# N32MC47x_DP47x register map
Vendor: Nsingtech Ltd.; File version: 1.0
Registers are 32-bit, read-write, reset 0x0 unless marked. A register's access mark holds for its fields unless they carry their own. Offsets are from the block's base; [hi:lo] are bit positions; 'fields as' and 'values as' point back to an identical list.

## FEMC — Flexible external memory controller
Base 0xA0002000
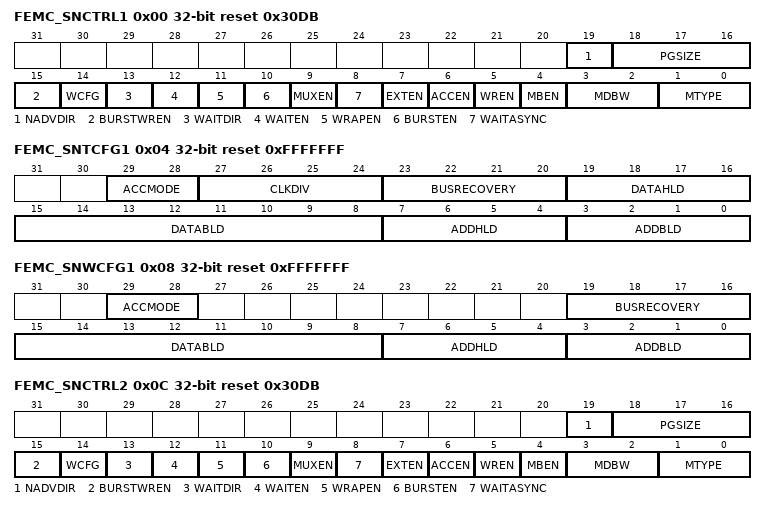
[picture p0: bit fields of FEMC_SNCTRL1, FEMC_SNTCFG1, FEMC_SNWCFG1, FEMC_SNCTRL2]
0x00 FEMC_SNCTRL1 reset 0x30DB
  [19] NADVDIR, [18:16] PGSIZE, [15] BURSTWREN, [14] WCFG, [13] WAITDIR, [12] WAITEN, [11] WRAPEN, [10] BURSTEN, [9] MUXEN, [8] WAITASYNC, [7] EXTEN, [6] ACCEN, [5] WREN, [4] MBEN, [3:2] MDBW, [1:0] MTYPE
0x04 FEMC_SNTCFG1 reset 0xFFFFFFF
  [29:28] ACCMODE, [27:24] CLKDIV, [23:20] BUSRECOVERY, [19:16] DATAHLD, [15:8] DATABLD, [7:4] ADDHLD, [3:0] ADDBLD
0x08 FEMC_SNWCFG1 reset 0xFFFFFFF
  [29:28] ACCMODE, [19:16] BUSRECOVERY, [15:8] DATABLD, [7:4] ADDHLD, [3:0] ADDBLD
0x0C FEMC_SNCTRL2 reset 0x30DB
  fields as FEMC_SNCTRL1
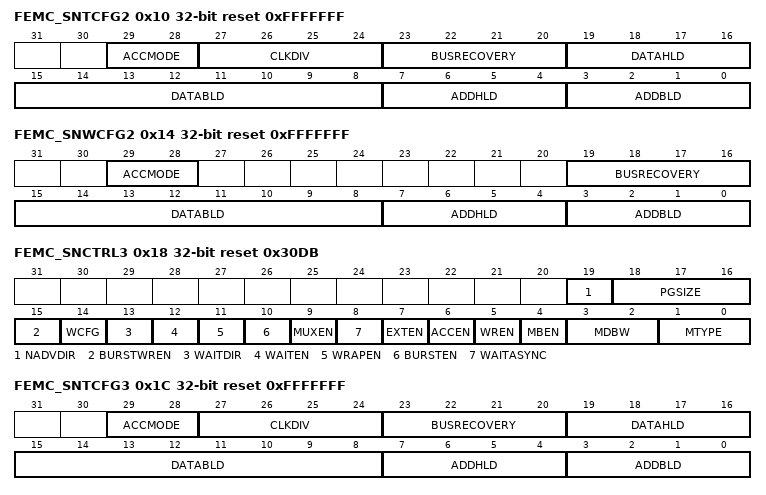
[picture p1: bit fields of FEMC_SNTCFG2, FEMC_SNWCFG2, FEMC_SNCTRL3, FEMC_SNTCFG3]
0x10 FEMC_SNTCFG2 reset 0xFFFFFFF
  fields as FEMC_SNTCFG1
0x14 FEMC_SNWCFG2 reset 0xFFFFFFF
  fields as FEMC_SNWCFG1
0x18 FEMC_SNCTRL3 reset 0x30DB
  fields as FEMC_SNCTRL1
0x1C FEMC_SNTCFG3 reset 0xFFFFFFF
  fields as FEMC_SNTCFG1
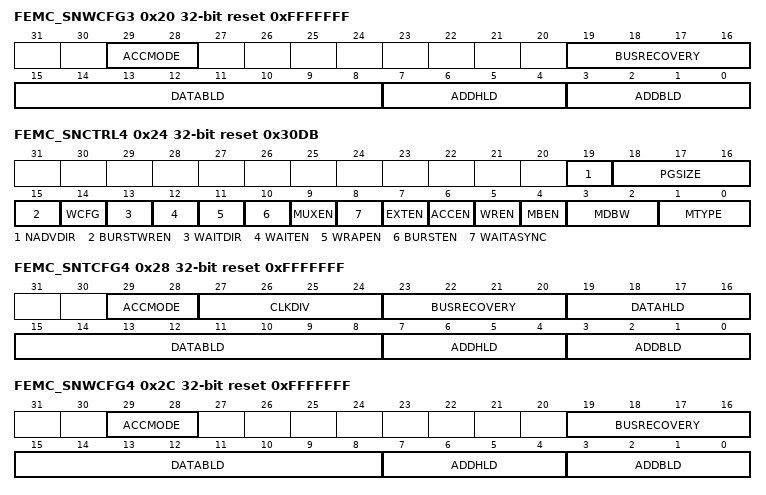
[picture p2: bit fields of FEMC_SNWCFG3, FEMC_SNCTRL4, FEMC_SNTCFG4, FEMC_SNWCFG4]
0x20 FEMC_SNWCFG3 reset 0xFFFFFFF
  fields as FEMC_SNWCFG1
0x24 FEMC_SNCTRL4 reset 0x30DB
  fields as FEMC_SNCTRL1
0x28 FEMC_SNTCFG4 reset 0xFFFFFFF
  fields as FEMC_SNTCFG1
0x2C FEMC_SNWCFG4 reset 0xFFFFFFF
  fields as FEMC_SNWCFG1
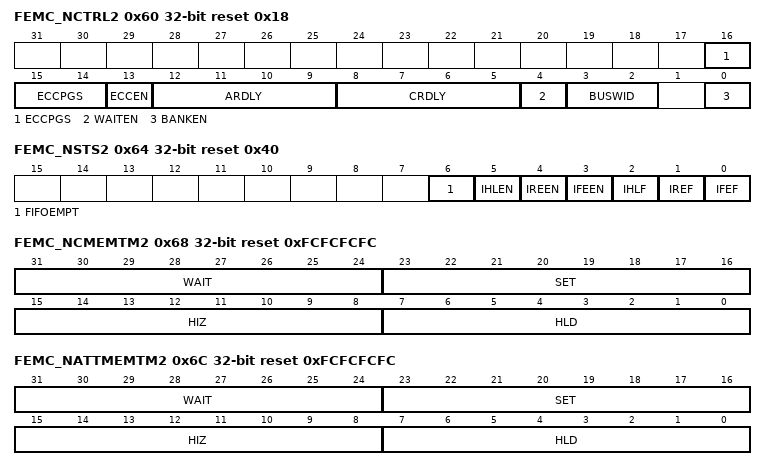
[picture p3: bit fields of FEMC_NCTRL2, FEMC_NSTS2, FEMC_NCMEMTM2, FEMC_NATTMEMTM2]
0x60 FEMC_NCTRL2 reset 0x18 (reset mask 0xFFE7E)
  [16:14] ECCPGS, [13] ECCEN, [12:9] ARDLY, [8:5] CRDLY, [4] WAITEN, [3:2] BUSWID, [0] BANKEN
0x64 FEMC_NSTS2 reset 0x40
  [6] FIFOEMPT, [5] IHLEN, [4] IREEN, [3] IFEEN, [2] IHLF, [1] IREF, [0] IFEF
0x68 FEMC_NCMEMTM2 reset 0xFCFCFCFC
  [31:24] WAIT, [23:16] SET, [15:8] HIZ, [7:0] HLD
0x6C FEMC_NATTMEMTM2 reset 0xFCFCFCFC
  [31:24] WAIT, [23:16] SET, [15:8] HIZ, [7:0] HLD
0x74 FEMC_ECC2 reset 0xFCFCFCFC
  [31:0] ECC
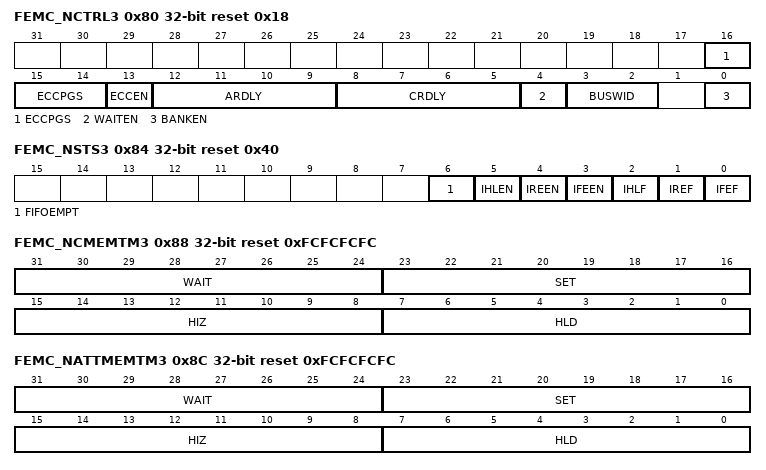
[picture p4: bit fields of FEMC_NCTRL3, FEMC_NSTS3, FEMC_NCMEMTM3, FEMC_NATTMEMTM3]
0x80 FEMC_NCTRL3 reset 0x18 (reset mask 0xFFE7E)
  fields as FEMC_NCTRL2
0x84 FEMC_NSTS3 reset 0x40
  fields as FEMC_NSTS2
0x88 FEMC_NCMEMTM3 reset 0xFCFCFCFC
  [31:24] WAIT, [23:16] SET, [15:8] HIZ, [7:0] HLD
0x8C FEMC_NATTMEMTM3 reset 0xFCFCFCFC
  [31:24] WAIT, [23:16] SET, [15:8] HIZ, [7:0] HLD
0x94 FEMC_ECC3 reset 0xFCFCFCFC
  [31:0] ECC

## FMAC — Filter math accelerator
Base 0x40021C00
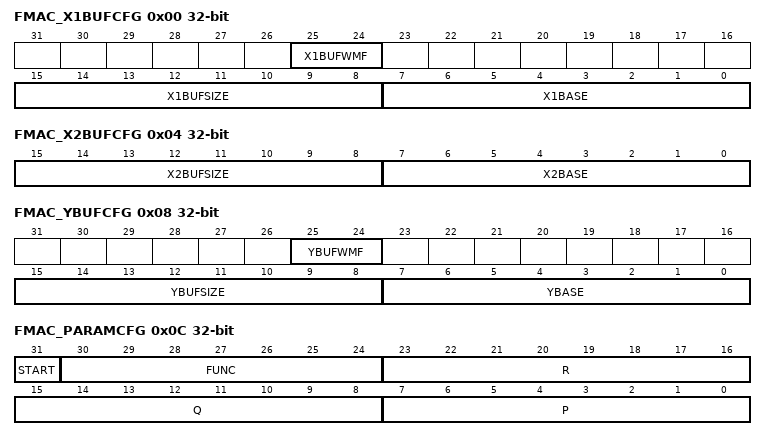
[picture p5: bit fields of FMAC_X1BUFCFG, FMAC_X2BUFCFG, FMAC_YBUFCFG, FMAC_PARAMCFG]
0x00 FMAC_X1BUFCFG
  [25:24] X1BUFWMF, [15:8] X1BUFSIZE, [7:0] X1BASE
0x04 FMAC_X2BUFCFG
  [15:8] X2BUFSIZE, [7:0] X2BASE
0x08 FMAC_YBUFCFG
  [25:24] YBUFWMF, [15:8] YBUFSIZE, [7:0] YBASE
0x0C FMAC_PARAMCFG
  [31] START, [30:24] FUNC, [23:16] R, [15:8] Q, [7:0] P
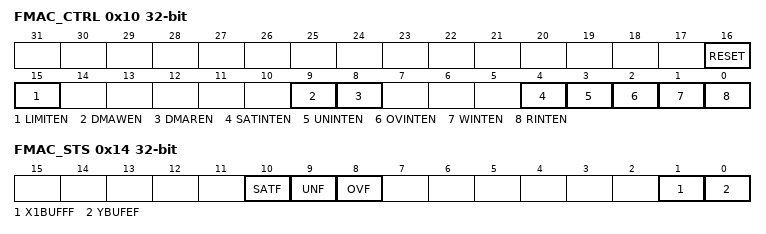
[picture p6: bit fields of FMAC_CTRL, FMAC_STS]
0x10 FMAC_CTRL
  [16] RESET, [15] LIMITEN, [9] DMAWEN, [8] DMAREN, [4] SATINTEN, [3] UNINTEN, [2] OVINTEN, [1] WINTEN, [0] RINTEN
0x14 FMAC_STS
  [10] SATF, [9] UNF, [8] OVF, [1] X1BUFFF, [0] YBUFEF
0x18 FMAC_WDAT
  [15:0] WDAT
0x1C FMAC_RDAT
  [15:0] RDAT

## CORDIC
Base 0x40022400
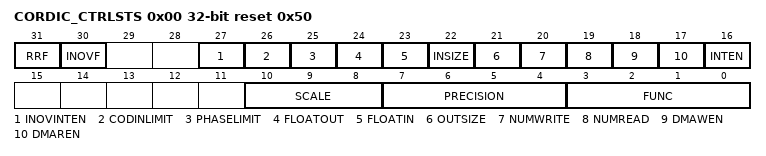
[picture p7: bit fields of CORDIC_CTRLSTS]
0x00 CORDIC_CTRLSTS reset 0x50
  [31] RRF, [30] INOVF, [27] INOVINTEN, [26] CODINLIMIT, [25] PHASELIMIT, [24] FLOATOUT, [23] FLOATIN, [22] INSIZE, [21] OUTSIZE, [20] NUMWRITE, [19] NUMREAD, [18] DMAWEN, [17] DMAREN, [16] INTEN, [10:8] SCALE, [7:4] PRECISION, [3:0] FUNC
0x04 CORDIC_WDAT
0x08 CORDIC_RDAT

## CRC — cyclic redundancy check
Base 0x40021800
0x00 CRC_CRC32CTRL
  [0] RESET
0x04 CRC_CRC32DAT reset 0xFFFFFFFF
0x08 CRC_CRC32IDAT
  [7:0] CRC32IDAT
0x0C CRC_CRC32D reset 0xFFFFFFFF
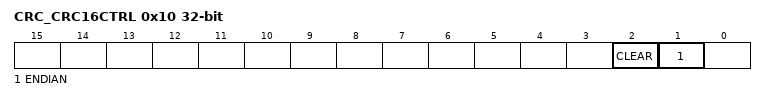
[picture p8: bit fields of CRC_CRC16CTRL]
0x10 CRC_CRC16CTRL
  [2] CLEAR, [1] ENDIAN
0x14 CRC_CRC16DAT
  [7:0] CRC16DAT
0x18 CRC_CRC16D
  [15:0] CRC16D
0x1C CRC_LRC
  [7:0] LRCDAT

## xSPI — Multi-line SPI
Base 0xA0001000
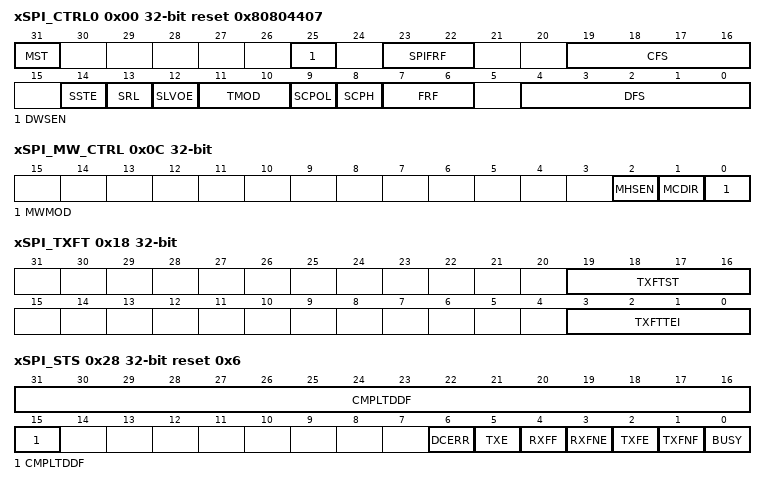
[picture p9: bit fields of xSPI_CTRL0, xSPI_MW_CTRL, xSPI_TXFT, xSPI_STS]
0x00 xSPI_CTRL0 reset 0x80804407
  [31] MST, [25] DWSEN, [23:22] SPIFRF, [19:16] CFS, [14] SSTE, [13] SRL, [12] SLVOE, [11:10] TMOD, [9] SCPOL, [8] SCPH, [7:6] FRF, [4:0] DFS
0x04 xSPI_CTRL1
  [15:0] NDF
0x08 xSPI_EN
  [0] xSPIEN
0x0C xSPI_MW_CTRL
  [2] MHSEN, [1] MCDIR, [0] MWMOD
0x10 xSPI_SLAVE_EN
  [1:0] SEN
0x14 xSPI_BAUD
  [15:1] CLKDIV
0x18 xSPI_TXFT
  [19:16] TXFTST, [3:0] TXFTTEI
0x1C xSPI_RXFT
  [3:0] RXFTTFI
0x20 xSPI_TXFN
  [4:0] TXFN
0x24 xSPI_RXFN
  [4:0] RXFN
0x28 xSPI_STS reset 0x6
  [31:15] CMPLTDDF, [6] DCERR, [5] TXE, [4] RXFF, [3] RXFNE, [2] TXFE, [1] TXFNF, [0] BUSY
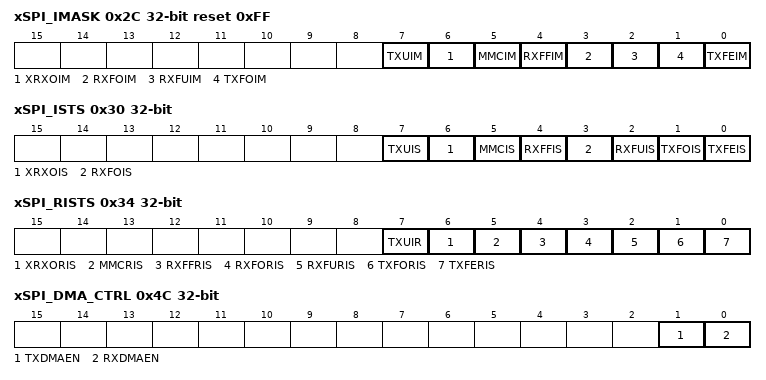
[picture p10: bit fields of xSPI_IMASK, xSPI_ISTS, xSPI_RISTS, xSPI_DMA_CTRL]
0x2C xSPI_IMASK reset 0xFF
  [7] TXUIM, [6] XRXOIM, [5] MMCIM, [4] RXFFIM, [3] RXFOIM, [2] RXFUIM, [1] TXFOIM, [0] TXFEIM
0x30 xSPI_ISTS
  [7] TXUIS, [6] XRXOIS, [5] MMCIS, [4] RXFFIS, [3] RXFOIS, [2] RXFUIS, [1] TXFOIS, [0] TXFEIS
0x34 xSPI_RISTS
  [7] TXUIR, [6] XRXORIS, [5] MMCRIS, [4] RXFFRIS, [3] RXFORIS, [2] RXFURIS, [1] TXFORIS, [0] TXFERIS
0x38 xSPI_TXEICR_CLR
  [0] TXEICR
0x3C xSPI_RXFOI_CLR
  [0] RXFOIC
0x40 xSPI_RXFUI_CLR
  [0] RXFUIC
0x44 xSPI_MMC_CLR
  [0] MMCIC
0x48 xSPI_ICLR
  [0] INTC
0x4C xSPI_DMA_CTRL
  [1] TXDMAEN, [0] RXDMAEN
0x50 xSPI_DMATDL_CTRL
  [3:0] DMATDL
0x54 xSPI_DMARDL_CTRL
  [3:0] DMARDL
0x58 xSPI_IDR reset 0xFFFF3621
  [31:0] IDCODE
0x5C xSPI_VERSION_ID reset 0x3130332A
  [31:0] VERSION
0x60 xSPI_DATx
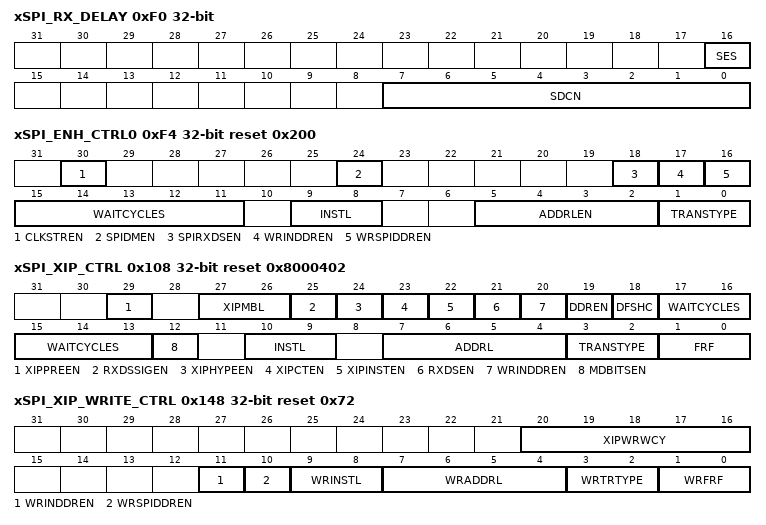
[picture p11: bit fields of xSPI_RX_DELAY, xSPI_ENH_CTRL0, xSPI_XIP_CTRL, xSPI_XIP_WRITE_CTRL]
0xF0 xSPI_RX_DELAY
  [16] SES, [7:0] SDCN
0xF4 xSPI_ENH_CTRL0 reset 0x200
  [30] CLKSTREN, [24] SPIDMEN, [18] SPIRXDSEN, [17] WRINDDREN, [16] WRSPIDDREN, [15:11] WAITCYCLES, [9:8] INSTL, [5:2] ADDRLEN, [1:0] TRANSTYPE
0xF8 xSPI_DDR_TXDE
  [7:0] TXDE
0xFC xSPI_XIP_MODE
  [15:0] XIPMDBITS
0x100 xSPI_XIP_INCR_TOC
  [15:0] ITOC
0x104 xSPI_XIP_WRAP_TOC
  [15:0] WTOC
0x108 xSPI_XIP_CTRL reset 0x8000402
  [29] XIPPREEN, [27:26] XIPMBL, [25] RXDSSIGEN, [24] XIPHYPEEN, [23] XIPCTEN, [22] XIPINSTEN, [21] RXDSEN, [20] WRINDDREN, [19] DDREN, [18] DFSHC, [17:13] WAITCYCLES, [12] MDBITSEN, [10:9] INSTL, [7:4] ADDRL, [3:2] TRANSTYPE, [1:0] FRF
0x10C xSPI_XIP_SLAVE_EN
  [1:0] SEN
0x110 xSPI_XIP_RXFOI_CLR
  [0] XRXFOIC
0x114 xSPI_XIP_TOUT
  [7:0] XTOUT
0x140 xSPI_XIP_WRITE_INCR_INST
  [15:0] INCRWRINST
0x144 xSPI_XIP_WRITE_WRAP_INST
  [15:0] WRAPWRINST
0x148 xSPI_XIP_WRITE_CTRL reset 0x72
  [20:16] XIPWRWCY, [11] WRINDDREN, [10] WRSPIDDREN, [9:8] WRINSTL, [7:4] WRADDRL, [3:2] WRTRTYPE, [1:0] WRFRF
